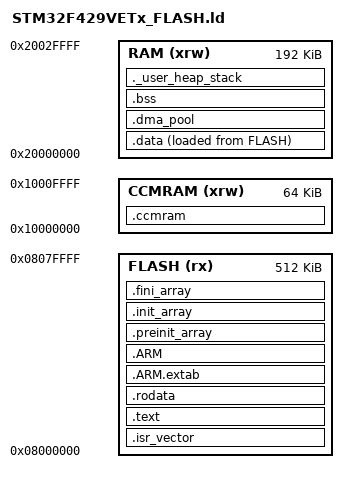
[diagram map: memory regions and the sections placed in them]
ENTRY(Reset_Handler)

_estack = ORIGIN(CCMRAM) + LENGTH(CCMRAM);

MEMORY
{
  FLASH  (rx)  : ORIGIN = 0x08000000, LENGTH = 512K
  RAM    (xrw) : ORIGIN = 0x20000000, LENGTH = 192K
  CCMRAM (xrw) : ORIGIN = 0x10000000, LENGTH = 64K
}

SECTIONS
{
  .isr_vector :
  {
    . = ALIGN(4);
    KEEP(*(.isr_vector))
    . = ALIGN(4);
  } >FLASH

  .text :
  {
    . = ALIGN(4);
    *(.text)
    *(.text*)
    *(.glue_7)
    *(.glue_7t)
    *(.eh_frame)
    KEEP(*(.init))
    KEEP(*(.fini))
    . = ALIGN(4);
    _etext = .;
  } >FLASH

  .rodata :
  {
    . = ALIGN(4);
    *(.rodata)
    *(.rodata*)
    . = ALIGN(4);
  } >FLASH

  .ARM.extab :
  {
    *(.ARM.extab* .gnu.linkonce.armextab.*)
  } >FLASH

  .ARM :
  {
    __exidx_start = .;
    *(.ARM.exidx*)
    __exidx_end = .;
  } >FLASH

  .preinit_array :
  {
    PROVIDE_HIDDEN(__preinit_array_start = .);
    KEEP(*(.preinit_array*))
    PROVIDE_HIDDEN(__preinit_array_end = .);
  } >FLASH

  .init_array :
  {
    PROVIDE_HIDDEN(__init_array_start = .);
    KEEP(*(SORT(.init_array.*)))
    KEEP(*(.init_array*))
    PROVIDE_HIDDEN(__init_array_end = .);
  } >FLASH

  .fini_array :
  {
    PROVIDE_HIDDEN(__fini_array_start = .);
    KEEP(*(SORT(.fini_array.*)))
    KEEP(*(.fini_array*))
    PROVIDE_HIDDEN(__fini_array_end = .);
  } >FLASH

  _sidata = LOADADDR(.data);

  .data :
  {
    . = ALIGN(4);
    _sdata = .;
    *(.data)
    *(.data*)
    . = ALIGN(4);
    _edata = .;
  } >RAM AT>FLASH

  .dma_pool (NOLOAD) :
  {
    . = ALIGN(32);
    KEEP(*(.dma_pool))
    . = ALIGN(32);
  } >RAM

  .bss (NOLOAD) :
  {
    . = ALIGN(4);
    _sbss = .;
    *(.bss)
    *(.bss*)
    *(COMMON)
    . = ALIGN(4);
    _ebss = .;
  } >RAM

  .ccmram (NOLOAD) :
  {
    . = ALIGN(4);
    *(.ccmram)
    *(.ccmram*)
    . = ALIGN(4);
  } >CCMRAM

  ._user_heap_stack (NOLOAD) :
  {
    . = ALIGN(8);
    PROVIDE(end = .);
    PROVIDE(_end = .);
    . = . + 0x1000;
    . = ALIGN(8);
  } >RAM
}

